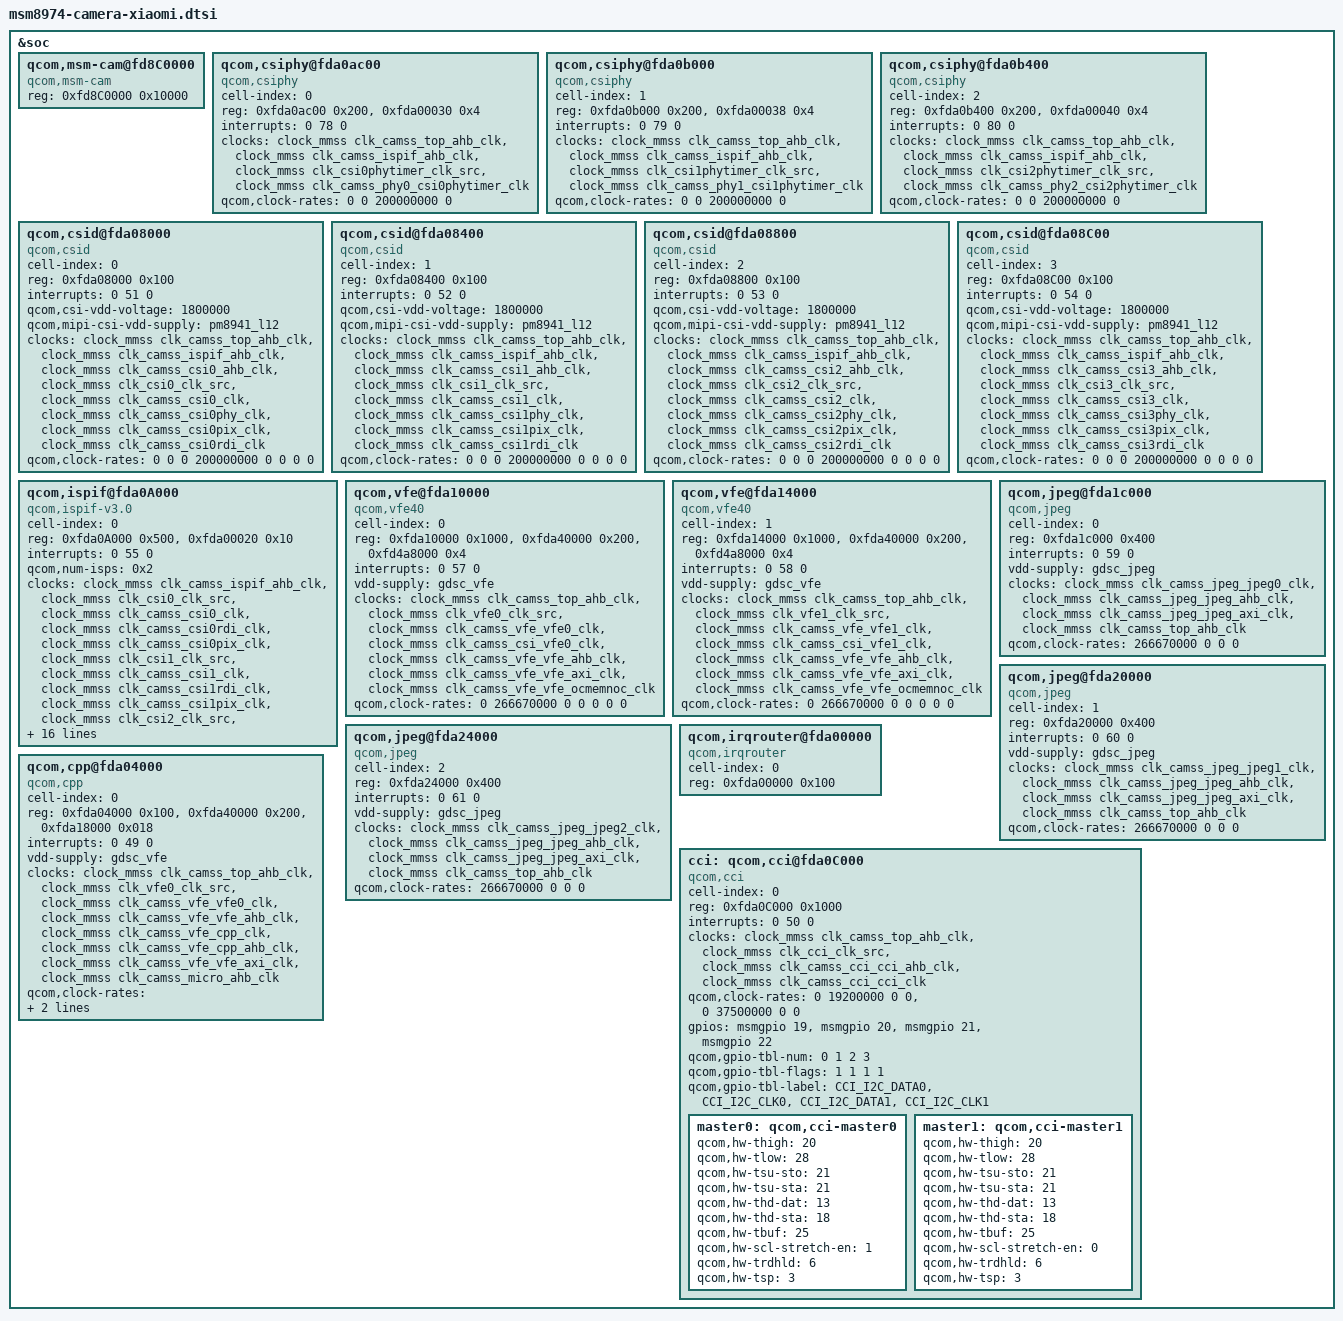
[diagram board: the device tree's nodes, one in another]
/*
 * Copyright (c) 2012-2013, The Linux Foundation. All rights reserved.
 * Copyright (C) 2015 XiaoMi, Inc.
 *
 * This program is free software; you can redistribute it and/or modify
 * it under the terms of the GNU General Public License version 2 and
 * only version 2 as published by the Free Software Foundation.
 *
 * This program is distributed in the hope that it will be useful,
 * but WITHOUT ANY WARRANTY; without even the implied warranty of
 * MERCHANTABILITY or FITNESS FOR A PARTICULAR PURPOSE.  See the
 * GNU General Public License for more details.
 */

&soc {
	qcom,msm-cam@fd8C0000 {
		compatible = "qcom,msm-cam";
		reg = <0xfd8C0000 0x10000>;
		reg-names = "msm-cam";
	};

	qcom,csiphy@fda0ac00 {
		cell-index = <0>;
		compatible = "qcom,csiphy";
		reg = <0xfda0ac00 0x200>,
                      <0xfda00030 0x4>;
		reg-names = "csiphy", "csiphy_clk_mux";
		interrupts = <0 78 0>;
		interrupt-names = "csiphy";
        clocks = <&clock_mmss clk_camss_top_ahb_clk>,
			<&clock_mmss clk_camss_ispif_ahb_clk>,
			<&clock_mmss clk_csi0phytimer_clk_src>,
			<&clock_mmss clk_camss_phy0_csi0phytimer_clk>;
		clock-names = "camss_top_ahb_clk",
			"ispif_ahb_clk", "csiphy_timer_src_clk",
			"csiphy_timer_clk";
		qcom,clock-rates = <0 0 200000000 0>;
	};

	qcom,csiphy@fda0b000 {
		cell-index = <1>;
		compatible = "qcom,csiphy";
		reg = <0xfda0b000 0x200>,
                      <0xfda00038 0x4>;
		reg-names = "csiphy", "csiphy_clk_mux";
		interrupts = <0 79 0>;
		interrupt-names = "csiphy";
        clocks = <&clock_mmss clk_camss_top_ahb_clk>,
			<&clock_mmss clk_camss_ispif_ahb_clk>,
			<&clock_mmss clk_csi1phytimer_clk_src>,
			<&clock_mmss clk_camss_phy1_csi1phytimer_clk>;
		clock-names = "camss_top_ahb_clk",
			"ispif_ahb_clk", "csiphy_timer_src_clk",
			"csiphy_timer_clk";
		qcom,clock-rates = <0 0 200000000 0>;
	};

	qcom,csiphy@fda0b400 {
		cell-index = <2>;
		compatible = "qcom,csiphy";
		reg = <0xfda0b400 0x200>,
                      <0xfda00040 0x4>;
		reg-names = "csiphy", "csiphy_clk_mux";
		interrupts = <0 80 0>;
		interrupt-names = "csiphy";
        clocks = <&clock_mmss clk_camss_top_ahb_clk>,
			<&clock_mmss clk_camss_ispif_ahb_clk>,
			<&clock_mmss clk_csi2phytimer_clk_src>,
			<&clock_mmss clk_camss_phy2_csi2phytimer_clk>;
		clock-names = "camss_top_ahb_clk",
			"ispif_ahb_clk", "csiphy_timer_src_clk",
			"csiphy_timer_clk";
		qcom,clock-rates = <0 0 200000000 0>;
	};

	qcom,csid@fda08000  {
		cell-index = <0>;
		compatible = "qcom,csid";
		reg = <0xfda08000 0x100>;
		reg-names = "csid";
		interrupts = <0 51 0>;
		interrupt-names = "csid";
		qcom,csi-vdd-voltage = <1800000>;
		qcom,mipi-csi-vdd-supply = <&pm8941_l12>;
        clocks = <&clock_mmss clk_camss_top_ahb_clk>,
			<&clock_mmss clk_camss_ispif_ahb_clk>,
			<&clock_mmss clk_camss_csi0_ahb_clk>,
			<&clock_mmss clk_csi0_clk_src>,
			<&clock_mmss clk_camss_csi0_clk>,
			<&clock_mmss clk_camss_csi0phy_clk>,
			<&clock_mmss clk_camss_csi0pix_clk>,
			<&clock_mmss clk_camss_csi0rdi_clk>;
		clock-names = "camss_top_ahb_clk", "ispif_ahb_clk",
			"csi_ahb_clk", "csi_src_clk", "csi_clk",
			"csi_phy_clk", "csi_pix_clk", "csi_rdi_clk";
		qcom,clock-rates = <0 0 0 200000000 0 0 0 0>;
	};

	qcom,csid@fda08400 {
		cell-index = <1>;
		compatible = "qcom,csid";
		reg = <0xfda08400 0x100>;
		reg-names = "csid";
		interrupts = <0 52 0>;
		interrupt-names = "csid";
		qcom,csi-vdd-voltage = <1800000>;
		qcom,mipi-csi-vdd-supply = <&pm8941_l12>;
        clocks = <&clock_mmss clk_camss_top_ahb_clk>,
			<&clock_mmss clk_camss_ispif_ahb_clk>,
			<&clock_mmss clk_camss_csi1_ahb_clk>,
			<&clock_mmss clk_csi1_clk_src>,
			<&clock_mmss clk_camss_csi1_clk>,
			<&clock_mmss clk_camss_csi1phy_clk>,
			<&clock_mmss clk_camss_csi1pix_clk>,
			<&clock_mmss clk_camss_csi1rdi_clk>;
		clock-names = "camss_top_ahb_clk", "ispif_ahb_clk",
			"csi_ahb_clk", "csi_src_clk", "csi_clk",
			"csi_phy_clk", "csi_pix_clk", "csi_rdi_clk";
		qcom,clock-rates = <0 0 0 200000000 0 0 0 0>;
	};

	qcom,csid@fda08800 {
		cell-index = <2>;
		compatible = "qcom,csid";
		reg = <0xfda08800 0x100>;
		reg-names = "csid";
		interrupts = <0 53 0>;
		interrupt-names = "csid";
		qcom,csi-vdd-voltage = <1800000>;
		qcom,mipi-csi-vdd-supply = <&pm8941_l12>;
        clocks = <&clock_mmss clk_camss_top_ahb_clk>,
			<&clock_mmss clk_camss_ispif_ahb_clk>,
			<&clock_mmss clk_camss_csi2_ahb_clk>,
			<&clock_mmss clk_csi2_clk_src>,
			<&clock_mmss clk_camss_csi2_clk>,
			<&clock_mmss clk_camss_csi2phy_clk>,
			<&clock_mmss clk_camss_csi2pix_clk>,
			<&clock_mmss clk_camss_csi2rdi_clk>;
		clock-names = "camss_top_ahb_clk", "ispif_ahb_clk",
			"csi_ahb_clk", "csi_src_clk", "csi_clk",
			"csi_phy_clk", "csi_pix_clk", "csi_rdi_clk";
		qcom,clock-rates = <0 0 0 200000000 0 0 0 0>;
	};

	qcom,csid@fda08C00 {
		cell-index = <3>;
		compatible = "qcom,csid";
		reg = <0xfda08C00 0x100>;
		reg-names = "csid";
		interrupts = <0 54 0>;
		interrupt-names = "csid";
		qcom,csi-vdd-voltage = <1800000>;
		qcom,mipi-csi-vdd-supply = <&pm8941_l12>;
        clocks = <&clock_mmss clk_camss_top_ahb_clk>,
			<&clock_mmss clk_camss_ispif_ahb_clk>,
			<&clock_mmss clk_camss_csi3_ahb_clk>,
			<&clock_mmss clk_csi3_clk_src>,
			<&clock_mmss clk_camss_csi3_clk>,
			<&clock_mmss clk_camss_csi3phy_clk>,
			<&clock_mmss clk_camss_csi3pix_clk>,
			<&clock_mmss clk_camss_csi3rdi_clk>;
		clock-names = "camss_top_ahb_clk", "ispif_ahb_clk",
			"csi_ahb_clk", "csi_src_clk", "csi_clk",
			"csi_phy_clk", "csi_pix_clk", "csi_rdi_clk";
		qcom,clock-rates = <0 0 0 200000000 0 0 0 0>;
	};

	qcom,ispif@fda0A000 {
		cell-index = <0>;
		compatible = "qcom,ispif-v3.0", "qcom,ispif";
		reg = <0xfda0A000 0x500>,
                      <0xfda00020 0x10>;
		reg-names = "ispif", "csi_clk_mux";
		interrupts = <0 55 0>;
		interrupt-names = "ispif";
		qcom,num-isps = <0x2>;
        clocks = <&clock_mmss clk_camss_ispif_ahb_clk>,
			<&clock_mmss clk_csi0_clk_src>,
			<&clock_mmss clk_camss_csi0_clk>,
			<&clock_mmss clk_camss_csi0rdi_clk>,
			<&clock_mmss clk_camss_csi0pix_clk>,
			<&clock_mmss clk_csi1_clk_src>,
			<&clock_mmss clk_camss_csi1_clk>,
			<&clock_mmss clk_camss_csi1rdi_clk>,
			<&clock_mmss clk_camss_csi1pix_clk>,
			<&clock_mmss clk_csi2_clk_src>,
			<&clock_mmss clk_camss_csi2_clk>,
			<&clock_mmss clk_camss_csi2rdi_clk>,
			<&clock_mmss clk_camss_csi2pix_clk>,
			<&clock_mmss clk_csi3_clk_src>,
			<&clock_mmss clk_camss_csi3_clk>,
			<&clock_mmss clk_camss_csi3rdi_clk>,
			<&clock_mmss clk_camss_csi3pix_clk>,
			<&clock_mmss clk_vfe0_clk_src>,
			<&clock_mmss clk_camss_vfe_vfe0_clk>,
			<&clock_mmss clk_camss_csi_vfe0_clk>,
			<&clock_mmss clk_vfe1_clk_src>,
			<&clock_mmss clk_camss_vfe_vfe1_clk>,
			<&clock_mmss clk_camss_csi_vfe1_clk>;
		clock-names = "ispif_ahb_clk",
			"csi0_src_clk", "csi0_clk",
			"csi0_pix_clk", "csi0_rdi_clk",
			"csi1_src_clk", "csi1_clk",
			"csi1_pix_clk", "csi1_rdi_clk",
			"csi2_src_clk", "csi2_clk",
			"csi2_pix_clk", "csi2_rdi_clk",
			"csi3_src_clk", "csi3_clk",
			"csi3_pix_clk", "csi3_rdi_clk",
			"vfe0_clk_src", "camss_vfe_vfe0_clk", "camss_csi_vfe0_clk",
			"vfe1_clk_src", "camss_vfe_vfe1_clk", "camss_csi_vfe1_clk";
		qcom,clock-rates = "0",
			"200000000", "0", "0", "0",
			"200000000", "0", "0", "0",
			"200000000", "0", "0", "0",
			"200000000", "0", "0", "0",
			"0", "0", "0",
			"0", "0", "0";
	};

	qcom,vfe@fda10000 {
		cell-index = <0>;
		compatible = "qcom,vfe40";
		reg = <0xfda10000 0x1000>,
			<0xfda40000 0x200>,
			<0xfd4a8000 0x4>;
		reg-names = "vfe", "vfe_vbif", "tcsr";
		interrupts = <0 57 0>;
		interrupt-names = "vfe";
		vdd-supply = <&gdsc_vfe>;
        clocks = <&clock_mmss clk_camss_top_ahb_clk>,
				<&clock_mmss clk_vfe0_clk_src>,
				<&clock_mmss clk_camss_vfe_vfe0_clk>,
				<&clock_mmss clk_camss_csi_vfe0_clk>,
				<&clock_mmss clk_camss_vfe_vfe_ahb_clk>,
				<&clock_mmss clk_camss_vfe_vfe_axi_clk>,
				<&clock_mmss clk_camss_vfe_vfe_ocmemnoc_clk>;
			clock-names = "camss_top_ahb_clk" , "vfe_clk_src",
				"camss_vfe_vfe_clk", "camss_csi_vfe_clk", "iface_clk",
				"bus_clk", "alt_bus_clk";
			qcom,clock-rates = <0 266670000 0 0 0 0 0>;
	};

	qcom,vfe@fda14000 {
		cell-index = <1>;
		compatible = "qcom,vfe40";
		reg = <0xfda14000 0x1000>,
			<0xfda40000 0x200>,
			<0xfd4a8000 0x4>;
		reg-names = "vfe", "vfe_vbif", "tcsr";
		interrupts = <0 58 0>;
		interrupt-names = "vfe";
		vdd-supply = <&gdsc_vfe>;
        clocks = <&clock_mmss clk_camss_top_ahb_clk>,
				<&clock_mmss clk_vfe1_clk_src>,
				<&clock_mmss clk_camss_vfe_vfe1_clk>,
				<&clock_mmss clk_camss_csi_vfe1_clk>,
				<&clock_mmss clk_camss_vfe_vfe_ahb_clk>,
				<&clock_mmss clk_camss_vfe_vfe_axi_clk>,
				<&clock_mmss clk_camss_vfe_vfe_ocmemnoc_clk>;
			clock-names = "camss_top_ahb_clk" , "vfe_clk_src",
				"camss_vfe_vfe_clk", "camss_csi_vfe_clk", "iface_clk",
				"bus_clk", "alt_bus_clk";
			qcom,clock-rates = <0 266670000 0 0 0 0 0>;
	};

	qcom,jpeg@fda1c000 {
		cell-index = <0>;
		compatible = "qcom,jpeg";
		reg = <0xfda1c000 0x400>;
		reg-names = "jpeg";
		interrupts = <0 59 0>;
		interrupt-names = "jpeg";
		vdd-supply = <&gdsc_jpeg>;
        clocks = <&clock_mmss clk_camss_jpeg_jpeg0_clk>,
			<&clock_mmss clk_camss_jpeg_jpeg_ahb_clk>,
			<&clock_mmss clk_camss_jpeg_jpeg_axi_clk>,
			<&clock_mmss clk_camss_top_ahb_clk>;
		clock-names = "core_clk", "iface_clk", "bus_clk0",
			"camss_top_ahb_clk";
		qcom,clock-rates = <266670000 0 0 0>;
	};

	qcom,jpeg@fda20000 {
		cell-index = <1>;
		compatible = "qcom,jpeg";
		reg = <0xfda20000 0x400>;
		reg-names = "jpeg";
		interrupts = <0 60 0>;
		interrupt-names = "jpeg";
		vdd-supply = <&gdsc_jpeg>;
        clocks = <&clock_mmss clk_camss_jpeg_jpeg1_clk>,
			<&clock_mmss clk_camss_jpeg_jpeg_ahb_clk>,
			<&clock_mmss clk_camss_jpeg_jpeg_axi_clk>,
			<&clock_mmss clk_camss_top_ahb_clk>;
		clock-names = "core_clk", "iface_clk", "bus_clk0",
			"camss_top_ahb_clk";
		qcom,clock-rates = <266670000 0 0 0>;
	};

	qcom,jpeg@fda24000 {
		cell-index = <2>;
		compatible = "qcom,jpeg";
		reg = <0xfda24000 0x400>;
		reg-names = "jpeg";
		interrupts = <0 61 0>;
		interrupt-names = "jpeg";
		vdd-supply = <&gdsc_jpeg>;
        clocks = <&clock_mmss clk_camss_jpeg_jpeg2_clk>,
			<&clock_mmss clk_camss_jpeg_jpeg_ahb_clk>,
			<&clock_mmss clk_camss_jpeg_jpeg_axi_clk>,
			<&clock_mmss clk_camss_top_ahb_clk>;
		clock-names = "core_clk", "iface_clk", "bus_clk0",
			"camss_top_ahb_clk";
		qcom,clock-rates = <266670000 0 0 0>;
	};

	qcom,irqrouter@fda00000 {
		cell-index = <0>;
		compatible = "qcom,irqrouter";
		reg = <0xfda00000 0x100>;
		reg-names = "irqrouter";
	};

	qcom,cpp@fda04000 {
		cell-index = <0>;
		compatible = "qcom,cpp";
		reg = <0xfda04000 0x100>,
			<0xfda40000 0x200>,
			<0xfda18000 0x018>;
		reg-names = "cpp", "cpp_vbif", "cpp_hw";
		interrupts = <0 49 0>;
		interrupt-names = "cpp";
		vdd-supply = <&gdsc_vfe>;
        clocks = <&clock_mmss clk_camss_top_ahb_clk>,
			<&clock_mmss clk_vfe0_clk_src>,
			<&clock_mmss clk_camss_vfe_vfe0_clk>,
			<&clock_mmss clk_camss_vfe_vfe_ahb_clk>,
			<&clock_mmss clk_camss_vfe_cpp_clk>,
			<&clock_mmss clk_camss_vfe_cpp_ahb_clk>,
			<&clock_mmss clk_camss_vfe_vfe_axi_clk>,
			<&clock_mmss clk_camss_micro_ahb_clk>;
		clock-names = "camss_top_ahb_clk", "vfe_clk_src",
                           "camss_vfe_vfe_clk", "iface_clk", "cpp_core_clk",
                           "cpp_iface_clk", "cpp_bus_clk", "micro_iface_clk";
		qcom,clock-rates = <0 266670000 0 0 266670000 0 0 0>;
		qcom,min-clock-rate = <266670000>;
	};

	cci: qcom,cci@fda0C000 {
		cell-index = <0>;
		compatible = "qcom,cci";
		reg = <0xfda0C000 0x1000>;
		#address-cells = <1>;
		#size-cells = <0>;
		reg-names = "cci";
		interrupts = <0 50 0>;
		interrupt-names = "cci";
        clocks = <&clock_mmss clk_camss_top_ahb_clk>,
			<&clock_mmss clk_cci_clk_src>,
			<&clock_mmss clk_camss_cci_cci_ahb_clk>,
			<&clock_mmss clk_camss_cci_cci_clk>;
		clock-names = "camss_top_ahb_clk", "cci_src_clk",
			"cci_ahb_clk", "cci_clk";
		qcom,clock-rates = <0 19200000 0 0>,
				<0 37500000 0 0>;
		gpios = <&msmgpio 19 0>,
			<&msmgpio 20 0>,
			<&msmgpio 21 0>,
			<&msmgpio 22 0>;
		qcom,gpio-tbl-num = <0 1 2 3>;
		qcom,gpio-tbl-flags = <1 1 1 1>;
		qcom,gpio-tbl-label = "CCI_I2C_DATA0",
				      "CCI_I2C_CLK0",
				      "CCI_I2C_DATA1",
				      "CCI_I2C_CLK1";
		master0: qcom,cci-master0 {
			status = "disabled";
		};
		master1: qcom,cci-master1 {
			status = "disabled";
		};
	};
};

&master0 {
	qcom,hw-thigh = <20>;
	qcom,hw-tlow = <28>;
	qcom,hw-tsu-sto = <21>;
	qcom,hw-tsu-sta = <21>;
	qcom,hw-thd-dat = <13>;
	qcom,hw-thd-sta = <18>;
	qcom,hw-tbuf = <25>;
	qcom,hw-scl-stretch-en = <1>;
	qcom,hw-trdhld = <6>;
	qcom,hw-tsp = <3>;
	status = "ok";
};

&master1 {
	qcom,hw-thigh = <20>;
	qcom,hw-tlow = <28>;
	qcom,hw-tsu-sto = <21>;
	qcom,hw-tsu-sta = <21>;
	qcom,hw-thd-dat = <13>;
	qcom,hw-thd-sta = <18>;
	qcom,hw-tbuf = <25>;
	qcom,hw-scl-stretch-en = <0>;
	qcom,hw-trdhld = <6>;
	qcom,hw-tsp = <3>;
	status = "ok";
};
